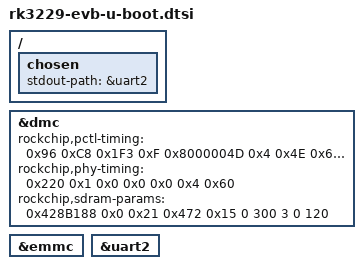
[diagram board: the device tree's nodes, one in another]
// SPDX-License-Identifier: (GPL-2.0+ OR MIT)

#include "rk322x-u-boot.dtsi"

/ {
	chosen {
		stdout-path = &uart2;
	};
};

&dmc {
	rockchip,pctl-timing = <0x96 0xC8 0x1F3 0xF 0x8000004D 0x4 0x4E 0x6 0x3
		0x0 0x6 0x5 0xC 0x10 0x6 0x4 0x4
		0x5 0x4 0x200 0x3 0xA 0x40 0x0 0x1
		0x5 0x5 0x3 0xC 0x1E 0x100 0x0 0x4
		0x0 0x924>;
	rockchip,phy-timing = <0x220 0x1 0x0 0x0 0x0 0x4 0x60>;
	rockchip,sdram-params = <0x428B188 0x0 0x21 0x472 0x15
		0 300 3 0 120>;
};

&emmc {
	bootph-all;
};

&uart2 {
	bootph-all;
};
